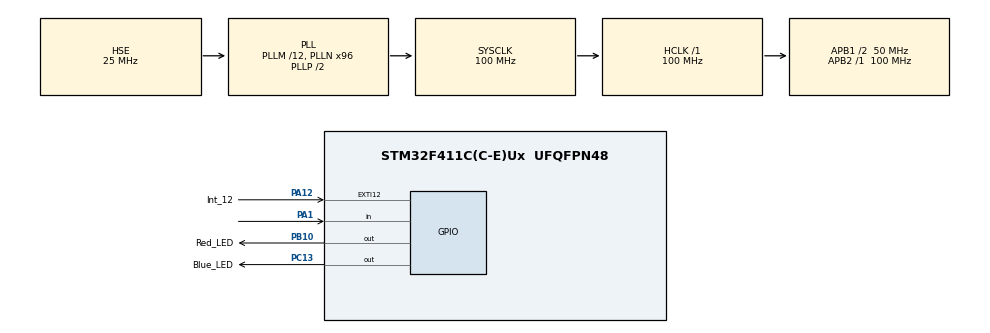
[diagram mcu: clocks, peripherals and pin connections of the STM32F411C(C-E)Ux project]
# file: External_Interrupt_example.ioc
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Mcu.Family=STM32F4
Mcu.Name=STM32F411C(C-E)Ux
Mcu.Package=UFQFPN48
NVIC.EXTI15_10_IRQn=true\:0\:0\:false\:false\:true\:true\:true\:true
NVIC.PriorityGroup=NVIC_PRIORITYGROUP_4
PA1.Signal=GPIO_Input
PA12.GPIO_Label=Int_12
PA12.GPIO_ModeDefaultEXTI=GPIO_MODE_IT_RISING_FALLING
PA12.GPIO_PuPd=GPIO_PULLUP
PA12.Signal=GPXTI12
PA13.Mode=Serial_Wire
PA13.Signal=SYS_JTMS-SWDIO
PA14.Mode=Serial_Wire
PA14.Signal=SYS_JTCK-SWCLK
PB10.GPIO_Label=Red_LED
PB10.GPIO_ModeDefaultOutputPP=GPIO_MODE_OUTPUT_OD
PB10.PinState=GPIO_PIN_SET
PB10.Signal=GPIO_Output
PC13-ANTI_TAMP.GPIO_Label=Blue_LED
PC13-ANTI_TAMP.GPIO_ModeDefaultOutputPP=GPIO_MODE_OUTPUT_OD
PC13-ANTI_TAMP.PinState=GPIO_PIN_SET
PC13-ANTI_TAMP.Signal=GPIO_Output
PH0\ -\ OSC_IN.Mode=HSE-External-Oscillator
PH0\ -\ OSC_IN.Signal=RCC_OSC_IN
PH1\ -\ OSC_OUT.Mode=HSE-External-Oscillator
PH1\ -\ OSC_OUT.Signal=RCC_OSC_OUT
ProjectManager.HeapSize=0x200
ProjectManager.StackSize=0x400
ProjectManager.TargetToolchain=STM32CubeIDE
RCC.48MHZClocksFreq_Value=50000000
RCC.AHBFreq_Value=100000000
RCC.APB1CLKDivider=RCC_HCLK_DIV2
RCC.APB1Freq_Value=50000000
RCC.APB1TimFreq_Value=100000000
RCC.APB2Freq_Value=100000000
RCC.APB2TimFreq_Value=100000000
RCC.CortexFreq_Value=100000000
RCC.HCLKFreq_Value=100000000
RCC.HSE_VALUE=25000000
RCC.HSI_VALUE=16000000
RCC.LSE_VALUE=32768
RCC.PLLM=12
RCC.PLLN=96
RCC.PLLSourceVirtual=RCC_PLLSOURCE_HSE
RCC.SYSCLKFreq_VALUE=100000000
RCC.SYSCLKSource=RCC_SYSCLKSOURCE_PLLCLK
RCC.VCOOutputFreq_Value=200000000
board=custom

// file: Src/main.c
/* USER CODE BEGIN Header */
/**
  ******************************************************************************
  * @file           : main.c
  * @brief          : Main program body
  ******************************************************************************
  * @attention
  *
  * <h2><center>&copy; Copyright (c) 2020 STMicroelectronics.
  * All rights reserved.</center></h2>
  *
  * This software component is licensed by ST under BSD 3-Clause license,
  * the "License"; You may not use this file except in compliance with the
  * License. You may obtain a copy of the License at:
  *                        opensource.org/licenses/BSD-3-Clause
  *
  ******************************************************************************
  */
/* USER CODE END Header */
#include "main.h"

void SystemClock_Config(void);
static void MX_GPIO_Init(void);

int main(void)
{

  /* MCU Configuration--------------------------------------------------------*/

  /* Reset of all peripherals, Initializes the Flash interface and the Systick. */
  HAL_Init();

  /* Configure the system clock */
  SystemClock_Config();

  /* Initialize all configured peripherals */
  MX_GPIO_Init();

  /* Infinite loop */
  /* USER CODE BEGIN WHILE */
  while (1)
  {
	  HAL_GPIO_TogglePin(Red_LED_GPIO_Port,Red_LED_Pin);
	  HAL_Delay(500);
    /* USER CODE END WHILE */

  }
}

void SystemClock_Config(void)
{
  RCC_OscInitTypeDef RCC_OscInitStruct = {0};
  RCC_ClkInitTypeDef RCC_ClkInitStruct = {0};

  /** Configure the main internal regulator output voltage
  */
  __HAL_RCC_PWR_CLK_ENABLE();
  __HAL_PWR_VOLTAGESCALING_CONFIG(PWR_REGULATOR_VOLTAGE_SCALE1);

  /** Initializes the RCC Oscillators according to the specified parameters
  * in the RCC_OscInitTypeDef structure.
  */
  RCC_OscInitStruct.OscillatorType = RCC_OSCILLATORTYPE_HSE;
  RCC_OscInitStruct.HSEState = RCC_HSE_ON;
  RCC_OscInitStruct.PLL.PLLState = RCC_PLL_ON;
  RCC_OscInitStruct.PLL.PLLSource = RCC_PLLSOURCE_HSE;
  RCC_OscInitStruct.PLL.PLLM = 12;
  RCC_OscInitStruct.PLL.PLLN = 96;
  RCC_OscInitStruct.PLL.PLLP = RCC_PLLP_DIV2;
  RCC_OscInitStruct.PLL.PLLQ = 4;
  if (HAL_RCC_OscConfig(&RCC_OscInitStruct) != HAL_OK)
  {
    Error_Handler();
  }

  /** Initializes the CPU, AHB and APB buses clocks
  */
  RCC_ClkInitStruct.ClockType = RCC_CLOCKTYPE_HCLK|RCC_CLOCKTYPE_SYSCLK
                              |RCC_CLOCKTYPE_PCLK1|RCC_CLOCKTYPE_PCLK2;
  RCC_ClkInitStruct.SYSCLKSource = RCC_SYSCLKSOURCE_PLLCLK;
  RCC_ClkInitStruct.AHBCLKDivider = RCC_SYSCLK_DIV1;
  RCC_ClkInitStruct.APB1CLKDivider = RCC_HCLK_DIV2;
  RCC_ClkInitStruct.APB2CLKDivider = RCC_HCLK_DIV1;

  if (HAL_RCC_ClockConfig(&RCC_ClkInitStruct, FLASH_LATENCY_3) != HAL_OK)
  {
    Error_Handler();
  }
}

static void MX_GPIO_Init(void)
{
  GPIO_InitTypeDef GPIO_InitStruct = {0};

  /* GPIO Ports Clock Enable */
  __HAL_RCC_GPIOC_CLK_ENABLE();
  __HAL_RCC_GPIOH_CLK_ENABLE();
  __HAL_RCC_GPIOA_CLK_ENABLE();
  __HAL_RCC_GPIOB_CLK_ENABLE();

  /*Configure GPIO pin Output Level */
  HAL_GPIO_WritePin(Blue_LED_GPIO_Port, Blue_LED_Pin, GPIO_PIN_SET);

  /*Configure GPIO pin Output Level */
  HAL_GPIO_WritePin(Red_LED_GPIO_Port, Red_LED_Pin, GPIO_PIN_SET);

  /*Configure GPIO pin : Blue_LED_Pin */
  GPIO_InitStruct.Pin = Blue_LED_Pin;
  GPIO_InitStruct.Mode = GPIO_MODE_OUTPUT_OD;
  GPIO_InitStruct.Pull = GPIO_NOPULL;
  GPIO_InitStruct.Speed = GPIO_SPEED_FREQ_LOW;
  HAL_GPIO_Init(Blue_LED_GPIO_Port, &GPIO_InitStruct);

  /*Configure GPIO pin : PA1 */
  GPIO_InitStruct.Pin = GPIO_PIN_1;
  GPIO_InitStruct.Mode = GPIO_MODE_INPUT;
  GPIO_InitStruct.Pull = GPIO_NOPULL;
  HAL_GPIO_Init(GPIOA, &GPIO_InitStruct);

  /*Configure GPIO pin : Red_LED_Pin */
  GPIO_InitStruct.Pin = Red_LED_Pin;
  GPIO_InitStruct.Mode = GPIO_MODE_OUTPUT_OD;
  GPIO_InitStruct.Pull = GPIO_NOPULL;
  GPIO_InitStruct.Speed = GPIO_SPEED_FREQ_LOW;
  HAL_GPIO_Init(Red_LED_GPIO_Port, &GPIO_InitStruct);

  /*Configure GPIO pin : Int_12_Pin */
  GPIO_InitStruct.Pin = Int_12_Pin;
  GPIO_InitStruct.Mode = GPIO_MODE_IT_RISING_FALLING;
  GPIO_InitStruct.Pull = GPIO_PULLUP;
  HAL_GPIO_Init(Int_12_GPIO_Port, &GPIO_InitStruct);

  /* EXTI interrupt init*/
  HAL_NVIC_SetPriority(EXTI15_10_IRQn, 0, 0);
  HAL_NVIC_EnableIRQ(EXTI15_10_IRQn);

}

/* USER CODE BEGIN 4 */
void HAL_GPIO_EXTI_Callback(uint16_t GPIO_Pin) //this is the return point from the interrupt handler in stm32f4xx_it.c bringing with it the interrupt pin number
{
	if (GPIO_Pin == Int_12_Pin) { //checks if interrupt pin is 12 and if so then executes the following code i.e. WritePin.  Additional if else statements can run additional ISRs
		HAL_GPIO_WritePin(Blue_LED_GPIO_Port, Blue_LED_Pin, HAL_GPIO_ReadPin(Int_12_GPIO_Port,Int_12_Pin));
	}
	else {
		__NOP ();
		__ASM volatile ("nop"); //this is a NOP in assembler, which is the same as the C HAL code __NOP (); The volatile keyword is intended to prevent the compiler from applying any optimisations
	}
}
/* USER CODE END 4 */

void Error_Handler(void)
{
  __disable_irq();
  while (1)
  {
  }
}
